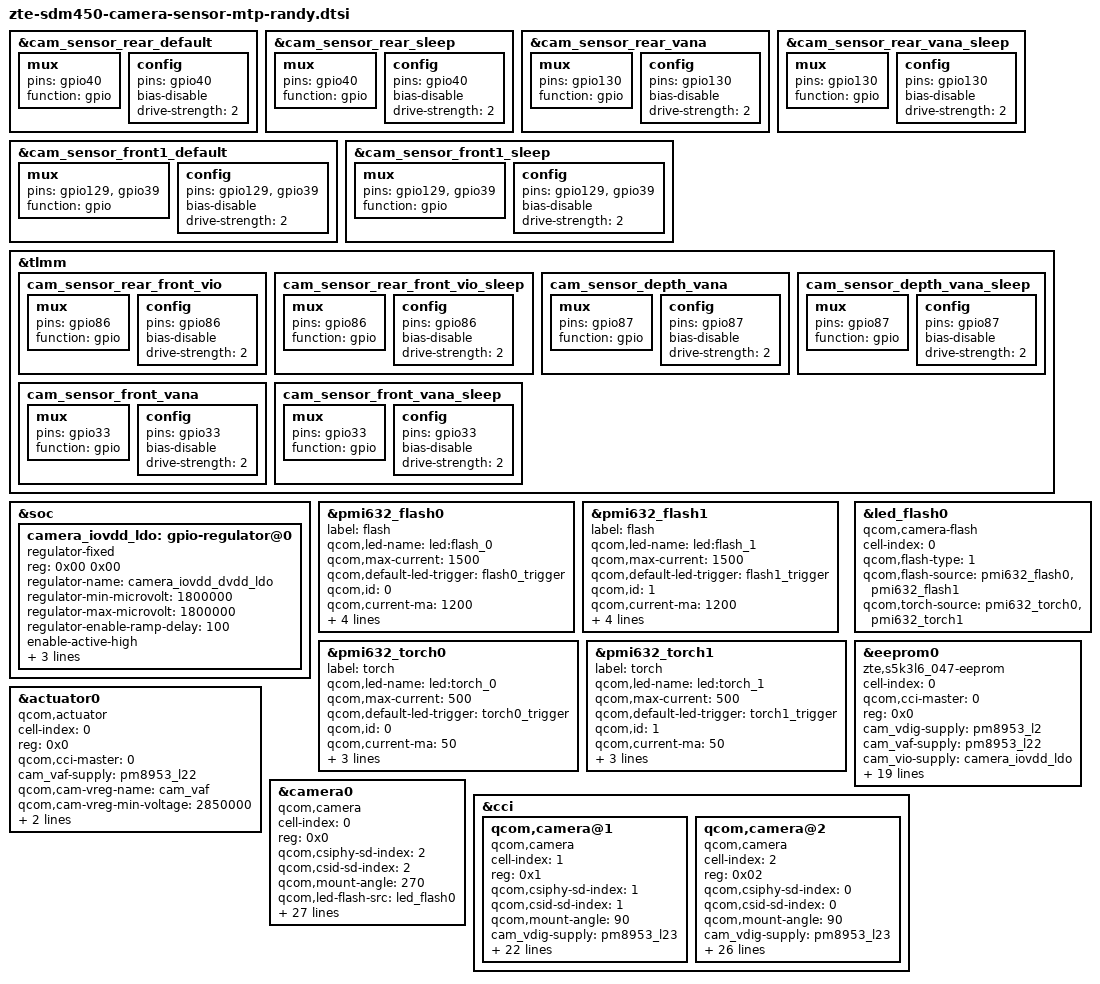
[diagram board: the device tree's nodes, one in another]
/*
 * Copyright (c) 2015-2018, The Linux Foundation. All rights reserved.
 *
 * This program is free software; you can redistribute it and/or modify
 * it under the terms of the GNU General Public License version 2 and
 * only version 2 as published by the Free Software Foundation.
 *
 * This program is distributed in the hope that it will be useful,
 * but WITHOUT ANY WARRANTY; without even the implied warranty of
 * MERCHANTABILITY or FITNESS FOR A PARTICULAR PURPOSE.  See the
 * GNU General Public License for more details.
 */
&cam_sensor_rear_default {
			mux {
				pins = "gpio40";
				function = "gpio";
			};

			config {
				pins = "gpio40";
				bias-disable;
				drive-strength = <2>;
			};
};
&cam_sensor_rear_sleep {
			mux {
				pins = "gpio40";
				function = "gpio";
			};

			config {
				pins = "gpio40";
				bias-disable;
				drive-strength = <2>;
			};
};
&cam_sensor_rear_vana {
			mux {
				pins = "gpio130";
				function = "gpio";
			};

			config {
				pins = "gpio130";
				bias-disable;
				drive-strength = <2>;
			};
};
&cam_sensor_rear_vana_sleep{
			mux {
				pins = "gpio130";
				function = "gpio";
			};

			config {
				pins = "gpio130";
				bias-disable;
				drive-strength = <2>;
			};
};
&cam_sensor_front1_default {
			mux {
				pins = "gpio129", "gpio39";
				function = "gpio";
			};

			config {
				pins = "gpio129", "gpio39";
				bias-disable;
				drive-strength = <2>;
			};
};

&cam_sensor_front1_sleep {
			mux {
				pins = "gpio129", "gpio39";
				function = "gpio";
			};

			config {
				pins = "gpio129", "gpio39";
				bias-disable;
				drive-strength = <2>;
			};
};

&tlmm{
	cam_sensor_rear_front_vio: cam_sensor_rear_front_vio {
		mux {
			pins = "gpio86";
			function = "gpio";
		};

		config {
			pins = "gpio86";
			bias-disable; /* No PULL */
			drive-strength = <2>; /* 2 MA */
		};
	};

	cam_sensor_rear_front_vio_sleep: cam_sensor_rear_front_vio_sleep {
		/* VIO */
		mux {
			pins = "gpio86";
			function = "gpio";
		};

		config {
			pins = "gpio86";
			bias-disable; /* No PULL */
			drive-strength = <2>; /* 2 MA */
		};
	};
	cam_sensor_depth_vana: cam_sensor_depth_vana {
		/* VANA */
		mux {
			pins = "gpio87";
			function = "gpio";
		};

		config {
			pins = "gpio87";
			bias-disable; /* No PULL */
			drive-strength = <2>; /* 2 MA */
		};
	};
	cam_sensor_depth_vana_sleep: cam_sensor_depth_vana_sleep {
		/* VANA */
		mux {
			pins = "gpio87";
			function = "gpio";
		};

		config {
			pins = "gpio87";
			bias-disable; /* No PULL */
			drive-strength = <2>; /* 2 MA */
		};
	};

	cam_sensor_front_vana: cam_sensor_front_vana {
		mux {
			pins = "gpio33";
			function = "gpio";
		};

		config {
			pins = "gpio33";
			bias-disable; /* No PULL */
			drive-strength = <2>; /* 2 MA */
		};
	};

	cam_sensor_front_vana_sleep: cam_sensor_front_vana_sleep {
		mux {
			pins = "gpio33";
			function = "gpio";
		};

		config {
			pins = "gpio33";
			bias-disable; /* No PULL */
			drive-strength = <2>; /* 2 MA */
		};
	};
};

&soc {
	camera_iovdd_ldo: gpio-regulator@0 {
		compatible = "regulator-fixed";
		reg = <0x00 0x00>;
		regulator-name = "camera_iovdd_dvdd_ldo";
		regulator-min-microvolt = <1800000>;
		regulator-max-microvolt = <1800000>;
		regulator-enable-ramp-delay = <100>;
		enable-active-high;
		gpio = <&tlmm 86 0>;
		pinctrl-names = "cam_sensor_rear_front_vio";
		pinctrl-0 = <&cam_sensor_rear_front_vio>;
		vin-supply = <&pm8953_s4>;
	};
};

&pmi632_flash0 {
	label = "flash";
	qcom,led-name = "led:flash_0";
	qcom,max-current = <1500>;
	qcom,default-led-trigger = "flash0_trigger";
	qcom,id = <0>;
	qcom,current-ma = <1200>;
	qcom,duration-ms = <1280>;
	qcom,ires-ua = <12500>;
	qcom,hdrm-voltage-mv = <400>;
	qcom,hdrm-vol-hi-lo-win-mv = <100>;
};

&pmi632_flash1 {
	label = "flash";
	qcom,led-name = "led:flash_1";
	qcom,max-current = <1500>;
	qcom,default-led-trigger = "flash1_trigger";
	qcom,id = <1>;
	qcom,current-ma = <1200>;
	qcom,duration-ms = <1280>;
	qcom,ires-ua = <12500>;
	qcom,hdrm-voltage-mv = <400>;
	qcom,hdrm-vol-hi-lo-win-mv = <100>;
};

&pmi632_torch0 {
	label = "torch";
	qcom,led-name = "led:torch_0";
	qcom,max-current = <500>;
	qcom,default-led-trigger = "torch0_trigger";
	qcom,id = <0>;
	qcom,current-ma = <50>;
	qcom,ires-ua = <12500>;
	qcom,hdrm-voltage-mv = <400>;
	qcom,hdrm-vol-hi-lo-win-mv = <100>;
};

&pmi632_torch1 {
	label = "torch";
	qcom,led-name = "led:torch_1";
	qcom,max-current = <500>;
	qcom,default-led-trigger = "torch1_trigger";
	qcom,id = <1>;
	qcom,current-ma = <50>;
	qcom,ires-ua = <12500>;
	qcom,hdrm-voltage-mv = <400>;
	qcom,hdrm-vol-hi-lo-win-mv = <100>;
};
&led_flash0{
	cell-index = <0>;
	compatible = "qcom,camera-flash";
	qcom,flash-type = <1>;
	qcom,flash-source = <&pmi632_flash0 &pmi632_flash1>;
	qcom,torch-source = <&pmi632_torch0 &pmi632_torch1>;
};

&actuator0{
	cell-index = <0>;
	reg = <0x0>;
	compatible = "qcom,actuator";
	qcom,cci-master = <0>;
	cam_vaf-supply = <&pm8953_l22>;
	qcom,cam-vreg-name = "cam_vaf";
	qcom,cam-vreg-min-voltage = <2850000>;
	qcom,cam-vreg-max-voltage = <2850000>;
	qcom,cam-vreg-op-mode = <80000>;
};

&eeprom0 {
	cell-index = <0>;
	compatible = "zte,s5k3l6_047-eeprom";
	qcom,cci-master = <0>;
	reg = <0x0>;
	cam_vdig-supply = <&pm8953_l2>;
	cam_vaf-supply = <&pm8953_l22>;
	cam_vio-supply = <&camera_iovdd_ldo>;
	qcom,cam-vreg-name = "cam_vdig", "cam_vaf", "cam_vio";
	qcom,cam-vreg-min-voltage = <1050000 2850000 1800000>;
	qcom,cam-vreg-max-voltage = <1050000 2850000 1800000>;
	qcom,cam-vreg-op-mode = <105000 100000 0>;
	pinctrl-names = "cam_default", "cam_suspend";
	pinctrl-0 = <&cam_sensor_mclk0_default
			&cam_sensor_rear_default
			&cam_sensor_rear_vana>;
	pinctrl-1 = <&cam_sensor_mclk0_sleep
			&cam_sensor_rear_sleep
			&cam_sensor_rear_vana_sleep>;
	gpios = <&tlmm 26 0>,
		<&tlmm 40 0>,
		<&tlmm 130 0>;
	qcom,gpio-reset = <1>;
	qcom,gpio-vana = <2>;
	qcom,gpio-req-tbl-num = <0 1 2>;
	qcom,gpio-req-tbl-flags = <1 0 0>;
	qcom,gpio-req-tbl-label = "CAMIF_MCLK0",
		"CAM_RESET0",
		"CAM_VANA";
	status = "ok";
};

/*main camera*/
&camera0{
	cell-index = <0>;
	compatible = "qcom,camera";
	reg = <0x0>;
	qcom,csiphy-sd-index = <2>;
	qcom,csid-sd-index = <2>;
	qcom,mount-angle = <270>;
	qcom,led-flash-src = <&led_flash0>;
	qcom,actuator-src = <&actuator0>;
	qcom,eeprom-src = <&eeprom0>;
	cam_vdig-supply = <&pm8953_l2>;
	cam_vaf-supply = <&pm8953_l22>;
	cam_vio-supply = <&camera_iovdd_ldo>;
	qcom,cam-vreg-name = "cam_vdig", "cam_vaf", "cam_vio";
	qcom,cam-vreg-min-voltage = <1050000 2850000 1800000>;
	qcom,cam-vreg-max-voltage = <1050000 2850000 1800000>;
	qcom,cam-vreg-op-mode = <105000 100000 0>;
	pinctrl-names = "cam_default", "cam_suspend";
	pinctrl-0 = <&cam_sensor_mclk0_default
			&cam_sensor_rear_default
			&cam_sensor_rear_vana>;
	pinctrl-1 = <&cam_sensor_mclk0_sleep
			&cam_sensor_rear_sleep
			&cam_sensor_rear_vana_sleep>;
	gpios = <&tlmm 26 0>,
		<&tlmm 40 0>,
		<&tlmm 130 0>;
	qcom,gpio-reset = <1>;
	qcom,gpio-vana = <2>;
	qcom,gpio-req-tbl-num = <0 1 2>;
	qcom,gpio-req-tbl-flags = <1 0 0>;
	qcom,gpio-req-tbl-label = "CAMIF_MCLK0",
		"CAM_RESET0",
		"CAM_VANA";
	qcom,sensor-position = <0>;
	qcom,sensor-mode = <0>;
	qcom,cci-master = <0>;
	status = "ok";
};

&cci {
/*depth camera*/
	qcom,camera@1 {
		cell-index = <1>;
		compatible = "qcom,camera";
		reg = <0x1>;
		qcom,csiphy-sd-index = <1>;
		qcom,csid-sd-index = <1>;
		qcom,mount-angle = <90>;
		cam_vdig-supply = <&pm8953_l23>;
		cam_vio-supply = <&camera_iovdd_ldo>;
		qcom,cam-vreg-name = "cam_vdig", "cam_vio";
		qcom,cam-vreg-min-voltage = <1200000 1800000>;
		qcom,cam-vreg-max-voltage = <1200000 1800000>;
		qcom,cam-vreg-op-mode = <200000 0>;
		pinctrl-names = "cam_default", "cam_suspend";
		pinctrl-0 = <&cam_sensor_mclk2_default
				&cam_sensor_front_default
				&cam_sensor_depth_vana>;
		pinctrl-1 = <&cam_sensor_mclk2_sleep
				&cam_sensor_front_sleep
				&cam_sensor_depth_vana_sleep>;
		gpios = <&tlmm 28 0>,
			<&tlmm 131 0>,
			<&tlmm 132 0>,
			<&tlmm 87 0>;
		qcom,gpio-reset = <1>;
		qcom,gpio-standby = <2>;
		qcom,gpio-vana = <3>;
		qcom,gpio-req-tbl-num = <0 1 2 3>;
		qcom,gpio-req-tbl-flags = <1 0 0 0>;
		qcom,gpio-req-tbl-label = "CAMIF_MCLK1",
			"CAM_RESET1",
			"CAM_STANDBY1",
			"CAM_VANA1";
		qcom,sensor-position = <0x100>;
		qcom,sensor-mode = <1>;
		qcom,cci-master = <1>;
		status = "ok";
	};
/*front camera*/
	qcom,camera@2 {
		cell-index = <2>;
		compatible = "qcom,camera";
		reg = <0x02>;
		qcom,csiphy-sd-index = <0>;
		qcom,csid-sd-index = <0>;
		qcom,mount-angle = <90>;
		cam_vdig-supply = <&pm8953_l23>;
		cam_vio-supply = <&camera_iovdd_ldo>;
		qcom,cam-vreg-name = "cam_vdig", "cam_vio";
		qcom,cam-vreg-min-voltage = <1200000 1800000>;
		qcom,cam-vreg-max-voltage = <1200000 1800000>;
		qcom,cam-vreg-op-mode = <105000 0>;
		pinctrl-names = "cam_default", "cam_suspend";
		pinctrl-0 = <&cam_sensor_mclk1_default
				&cam_sensor_front1_default
				&cam_sensor_front_vana
				&cam_sensor_rear_front_vio>;
		pinctrl-1 = <&cam_sensor_mclk1_sleep
				&cam_sensor_front1_sleep
				&cam_sensor_front_vana_sleep
				&cam_sensor_rear_front_vio_sleep>;
		gpios = <&tlmm 27 0>,
			<&tlmm 129 0>,
			<&tlmm 39 0>,
			<&tlmm 33 0>,
			<&tlmm 86 0>;
		qcom,gpio-reset = <1>;
		qcom,gpio-standby = <2>;
		qcom,gpio-vana = <3>;
		qcom,gpio-vio = <4>;
		qcom,gpio-req-tbl-num = <0 1 2 3 4>;
		qcom,gpio-req-tbl-flags = <1 0 0 0 0>;
		qcom,gpio-req-tbl-label = "CAMIF_MCLK2",
					  "CAM_RESET2",
					  "CAM_STANDBY2",
					  "CAM_VANA2",
					  "CAM_VIO";
		qcom,sensor-position = <1>;
		qcom,sensor-mode = <0>;
		qcom,cci-master = <1>;
		status = "ok";
	};
};
